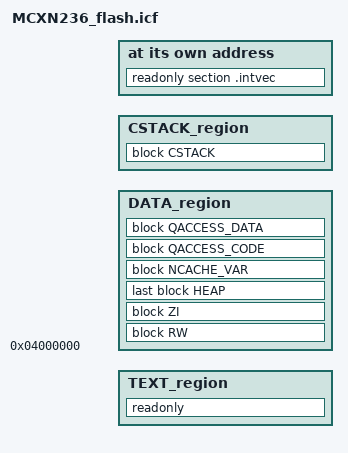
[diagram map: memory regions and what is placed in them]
/*
** ###################################################################
**     Processors:          MCXN236VDF
**                          MCXN236VKL
**                          MCXN236VNL
**                          MCXN236VPB
**
**     Compiler:            IAR ANSI C/C++ Compiler for ARM
**     Reference manual:    MCXN23XRM
**     Version:             rev. 1.0, 2021-08-03
**     Build:               b241105
**
**     Abstract:
**         Linker file for the IAR ANSI C/C++ Compiler for ARM
**
**     Copyright 2016 Freescale Semiconductor, Inc.
**     Copyright 2016-2024 NXP
**     SPDX-License-Identifier: BSD-3-Clause
**
**     http:                 www.nxp.com
**     mail:                 support@nxp.com
**
** ###################################################################
*/


/* USB BDT size */
define symbol usb_bdt_size             = 0x0;
/* Stack and Heap Sizes */
if (isdefinedsymbol(__stack_size__)) {
  define symbol __size_cstack__        = __stack_size__;
} else {
  define symbol __size_cstack__        = 0x0400;
}

if (isdefinedsymbol(__heap_size__)) {
  define symbol __size_heap__          = __heap_size__;
} else {
  define symbol __size_heap__          = 0x0400;
}

/*
  Flash partition layout selector - this single linker file covers both
  supported layouts. The custom one is selected by the __mcuboot_main_flash_only__
  linker symbol, which is defined by the mcuboot middleware when the Kconfig
  option MCUX_COMPONENT_middleware.mcuboot.mcxn_custom_cfg.main_flash_only
  is enabled. See flash_partitioning.h of the mcuboot_opensource example.

  Default configuration (__mcuboot_main_flash_only__ not defined)
  Bootloader located in Bank 1 IFR 0 Region (0x0100_8000 - 0x0100_FFFF)
  This configuration supports flash remap

  0x0000_0000  +------------------------+ Flash Start
               | Application_Primary    | 512 kB
  0x0008_0000  +------------------------+
               | Application_Secondary  | 512 kB
  0x0010_0000  +------------------------+
                          ...
  0x0100_8000  +------------------------+
               | Bootloader             | 32 kB   <- this image
  0x0100_FFFF  +------------------------+

  Custom configuration (__mcuboot_main_flash_only__ defined)
  Bootloader located in main flash
  This configuration supports mbedTLS by default

  0x0000_0000  +------------------------+ Flash Start
               | Bootloader             | 256 kB  <- this image
  0x0004_0000  +------------------------+
               | Application_Primary    | 384 kB
  0x000A_0000  +------------------------+
               | Application_Secondary  | 384 kB
  0x0010_0000  +------------------------+

  RAM: 0x2000_0000 - 0x2003_7FFF (224 kB), SRAMX 0x0400_0000 - 0x0401_7FFF (96 kB)

  Note: the custom configuration addresses the flash and RAM through their
  secure aliases (0x1000_0000 / 0x3000_0000), the default one through the
  non-secure aliases (0x0000_0000 / 0x2000_0000).
*/

define symbol m_interrupts_start               = isdefinedsymbol(__mcuboot_main_flash_only__) ? 0x10000000 : 0x01008000;
define symbol m_interrupts_end                 = isdefinedsymbol(__mcuboot_main_flash_only__) ? 0x100003FF : 0x010083FF;

define symbol m_text_start                     = isdefinedsymbol(__mcuboot_main_flash_only__) ? 0x10000400 : 0x01008400;
define symbol m_text_end                       = isdefinedsymbol(__mcuboot_main_flash_only__) ? 0x1003FFFF : 0x0100FFFF;

define symbol m_data_base                      = isdefinedsymbol(__mcuboot_main_flash_only__) ? 0x30000000 : 0x20000000;

define symbol m_data_start                     = m_data_base;
define symbol m_data_end                       = m_data_base + 0x00037FFF;

define symbol m_sramx_start                    = 0x04000000;
define symbol m_sramx_end                      = 0x04017FFF;


define memory mem with size = 4G;

define region TEXT_region             = mem:[from m_interrupts_start to m_interrupts_end]
                                      | mem:[from m_text_start to m_text_end];

define region DATA_region = mem:[from m_data_start to m_data_end-__size_cstack__] |
                            mem:[from m_sramx_start to m_sramx_end];
define region CSTACK_region = mem:[from m_data_end-__size_cstack__+1 to m_data_end];

define block CSTACK        with alignment = 8, size = __size_cstack__   { };
define block HEAP          with alignment = 8, size = __size_heap__     { };
define block RW            { readwrite };
define block ZI            { zi };
define block NCACHE_VAR    { section NonCacheable , section NonCacheable.init };
define block QACCESS_CODE  { section CodeQuickAccess };
define block QACCESS_DATA  { section DataQuickAccess };

initialize by copy { readwrite, section .textrw };

if (isdefinedsymbol(__USE_DLIB_PERTHREAD))
{
  /* Required in a multi-threaded application */
  initialize by copy with packing = none { section __DLIB_PERTHREAD };
}

place at address mem: m_interrupts_start    { readonly section .intvec };
place in TEXT_region                        { readonly };
place in DATA_region                        { block RW };
place in DATA_region                        { block ZI };
place in DATA_region                        { last block HEAP };
place in CSTACK_region                      { block CSTACK };
place in DATA_region                        { block NCACHE_VAR };
place in DATA_region                        { block QACCESS_CODE };
place in DATA_region                        { block QACCESS_DATA };
